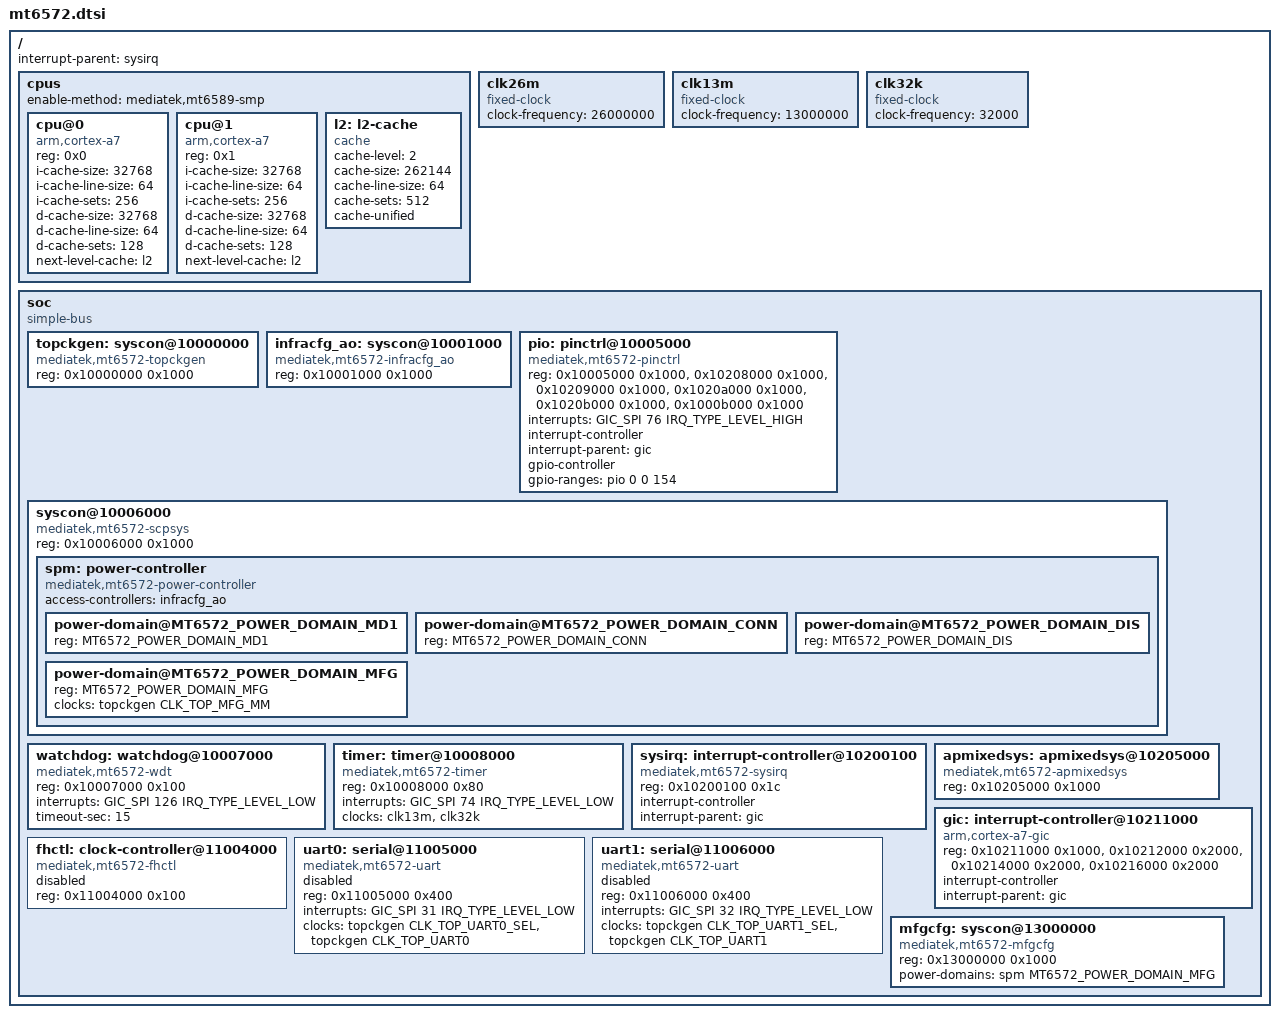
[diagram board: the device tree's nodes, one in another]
// SPDX-License-Identifier: GPL-2.0
/*
 * Copyright (c) 2025 Max Shevchenko <wctrl@proton.me>
 */

#include <dt-bindings/interrupt-controller/irq.h>
#include <dt-bindings/interrupt-controller/arm-gic.h>
#include <dt-bindings/clock/mediatek,mt6572-clk.h>
#include <dt-bindings/reset/mediatek,mt6572-resets.h>
#include <dt-bindings/power/mediatek,mt6572-power-controller.h>
#include <dt-bindings/pinctrl/mediatek,mt6572-pinfunc.h>

/ {
	#address-cells = <1>;
	#size-cells = <1>;
	interrupt-parent = <&sysirq>;

	cpus {
		#address-cells = <1>;
		#size-cells = <0>;
		enable-method = "mediatek,mt6589-smp";

		cpu@0 {
			device_type = "cpu";
			compatible = "arm,cortex-a7";
			reg = <0x0>;
			i-cache-size = <32768>;
			i-cache-line-size = <64>;
			i-cache-sets = <256>;
			d-cache-size = <32768>;
			d-cache-line-size = <64>;
			d-cache-sets = <128>;
			next-level-cache = <&l2>;
		};
		cpu@1 {
			device_type = "cpu";
			compatible = "arm,cortex-a7";
			reg = <0x1>;
			i-cache-size = <32768>;
			i-cache-line-size = <64>;
			i-cache-sets = <256>;
			d-cache-size = <32768>;
			d-cache-line-size = <64>;
			d-cache-sets = <128>;
			next-level-cache = <&l2>;
		};

		l2: l2-cache {
			compatible = "cache";
			cache-level = <2>;
			cache-size = <262144>;
			cache-line-size = <64>;
			cache-sets = <512>;
			cache-unified;
		};
	};

	clk26m: clk26m {
		compatible = "fixed-clock";
		clock-frequency = <26000000>;
		#clock-cells = <0>;
	};

	clk13m: clk13m {
		compatible = "fixed-clock";
		clock-frequency = <13000000>;
		#clock-cells = <0>;
	};

	clk32k: clk32k {
		compatible = "fixed-clock";
		clock-frequency = <32000>;
		#clock-cells = <0>;
	};

	soc {
		#address-cells = <1>;
		#size-cells = <1>;
		compatible = "simple-bus";
		ranges;

		topckgen: syscon@10000000 {
			compatible = "mediatek,mt6572-topckgen", "syscon";
			reg = <0x10000000 0x1000>;
			#clock-cells = <1>;
		};

		infracfg_ao: syscon@10001000 {
			compatible = "mediatek,mt6572-infracfg_ao", "syscon";
			reg = <0x10001000 0x1000>;
			#access-controller-cells = <0>;
			#clock-cells = <1>;
		};

		pio: pinctrl@10005000 {
			compatible = "mediatek,mt6572-pinctrl";
			reg = <0x10005000 0x1000>,
			      <0x10208000 0x1000>,
			      <0x10209000 0x1000>,
			      <0x1020a000 0x1000>,
			      <0x1020b000 0x1000>,
			      <0x1000b000 0x1000>;
			reg-names = "base", "iocfg_t", "iocfg_b",
				    "iocfg_l", "iocfg_r", "eint";
			interrupts = <GIC_SPI 76 IRQ_TYPE_LEVEL_HIGH>;
			interrupt-controller;
			interrupt-parent = <&gic>;
			#interrupt-cells = <2>;
			gpio-controller;
			gpio-ranges = <&pio 0 0 154>;
			#gpio-cells = <2>;
		};

		syscon@10006000 {
			compatible = "mediatek,mt6572-scpsys", "syscon", "simple-mfd";
			reg = <0x10006000 0x1000>;

			spm: power-controller {
				compatible = "mediatek,mt6572-power-controller";
				#address-cells = <1>;
				#size-cells = <0>;
				#power-domain-cells = <1>;
				access-controllers = <&infracfg_ao>;

				power-domain@MT6572_POWER_DOMAIN_MD1 {
					reg = <MT6572_POWER_DOMAIN_MD1>;
					#power-domain-cells = <0>;
				};

				power-domain@MT6572_POWER_DOMAIN_CONN {
					reg = <MT6572_POWER_DOMAIN_CONN>;
					#power-domain-cells = <0>;
				};

				power-domain@MT6572_POWER_DOMAIN_DIS {
					reg = <MT6572_POWER_DOMAIN_DIS>;
					#power-domain-cells = <0>;
				};

				power-domain@MT6572_POWER_DOMAIN_MFG {
					reg = <MT6572_POWER_DOMAIN_MFG>;
					#power-domain-cells = <0>;
					clocks = <&topckgen CLK_TOP_MFG_MM>;
					clock-names = "mfg";
				};
			};
		};

		watchdog: watchdog@10007000 {
			compatible = "mediatek,mt6572-wdt", "mediatek,mt6589-wdt";
			reg = <0x10007000 0x100>;
			interrupts = <GIC_SPI 126 IRQ_TYPE_LEVEL_LOW>;
			timeout-sec = <15>;
			#reset-cells = <1>;
		};

		timer: timer@10008000 {
			compatible = "mediatek,mt6572-timer", "mediatek,mt6577-timer";
			reg = <0x10008000 0x80>;
			interrupts = <GIC_SPI 74 IRQ_TYPE_LEVEL_LOW>;
			clocks = <&clk13m>, <&clk32k>;
			clock-names = "system-clk", "rtc-clk";
		};

		sysirq: interrupt-controller@10200100 {
			compatible = "mediatek,mt6572-sysirq", "mediatek,mt6577-sysirq";
			reg = <0x10200100 0x1c>;
			interrupt-controller;
			#interrupt-cells = <3>;
			interrupt-parent = <&gic>;
		};

		apmixedsys: apmixedsys@10205000 {
			compatible = "mediatek,mt6572-apmixedsys", "syscon";
			reg = <0x10205000 0x1000>;
			#clock-cells = <1>;
		};

		gic: interrupt-controller@10211000 {
			compatible = "arm,cortex-a7-gic";
			reg = <0x10211000 0x1000>,
			      <0x10212000 0x2000>,
			      <0x10214000 0x2000>,
			      <0x10216000 0x2000>;
			interrupt-controller;
			#interrupt-cells = <3>;
			interrupt-parent = <&gic>;
		};

		fhctl: clock-controller@11004000 {
			compatible = "mediatek,mt6572-fhctl";
			reg = <0x11004000 0x100>;
			status = "disabled";
		};

		uart0: serial@11005000 {
			compatible = "mediatek,mt6572-uart", "mediatek,mt6577-uart";
			reg = <0x11005000 0x400>;
			interrupts = <GIC_SPI 31 IRQ_TYPE_LEVEL_LOW>;
			clocks = <&topckgen CLK_TOP_UART0_SEL>,
				 <&topckgen CLK_TOP_UART0>;
			clock-names = "baud", "bus";
			status = "disabled";
		};

		uart1: serial@11006000 {
			compatible = "mediatek,mt6572-uart", "mediatek,mt6577-uart";
			reg = <0x11006000 0x400>;
			interrupts = <GIC_SPI 32 IRQ_TYPE_LEVEL_LOW>;
			clocks = <&topckgen CLK_TOP_UART1_SEL>,
				 <&topckgen CLK_TOP_UART1>;
			clock-names = "baud", "bus";
			status = "disabled";
		};

		mfgcfg: syscon@13000000 {
			compatible = "mediatek,mt6572-mfgcfg", "syscon";
			reg = <0x13000000 0x1000>;
			#clock-cells = <1>;
			power-domains = <&spm MT6572_POWER_DOMAIN_MFG>;
		};
	};
};
